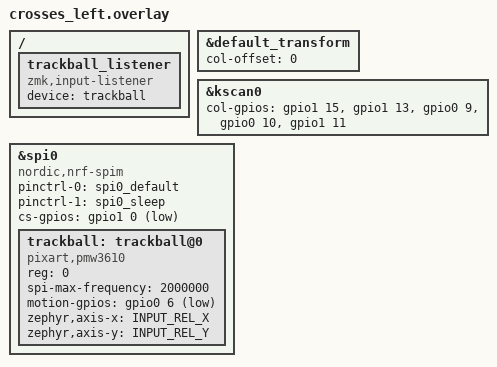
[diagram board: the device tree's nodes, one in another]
#include "crosses.dtsi"
#include <dt-bindings/zmk/mouse.h>
#include <zephyr/dt-bindings/input/input-event-codes.h>

&default_transform {
    col-offset = <0>; /* 左手のキー配置 */
};

/* 左手の配線設定 */
&kscan0 {
    col-gpios
        = <&gpio1 15 (GPIO_ACTIVE_HIGH | GPIO_PULL_DOWN)>
        , <&gpio1 13 (GPIO_ACTIVE_HIGH | GPIO_PULL_DOWN)>
        , <&gpio0 9 (GPIO_ACTIVE_HIGH | GPIO_PULL_DOWN)>
        , <&gpio0 10 (GPIO_ACTIVE_HIGH | GPIO_PULL_DOWN)>
        , <&gpio1 11 (GPIO_ACTIVE_HIGH | GPIO_PULL_DOWN)>
        ;
};

/* トラックボールを左手でも有効にする記述 */
&spi0 {
    status = "okay";
    compatible = "nordic,nrf-spim";
    pinctrl-0 = <&spi0_default>;
    pinctrl-1 = <&spi0_sleep>;
    pinctrl-names = "default", "sleep";
    cs-gpios = <&gpio1 0 GPIO_ACTIVE_LOW>;

    trackball: trackball@0 {
        status = "okay";
        compatible = "pixart,pmw3610";
        reg = <0>;
        spi-max-frequency = <2000000>;
        motion-gpios = <&gpio0 6 (GPIO_ACTIVE_LOW | GPIO_PULL_UP)>;
        zephyr,axis-x = <INPUT_REL_X>;
        zephyr,axis-y = <INPUT_REL_Y>;
    };
};

/ {
    trackball_listener {
        compatible = "zmk,input-listener";
        device = <&trackball>;
    };
};
